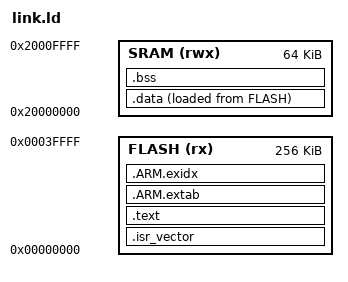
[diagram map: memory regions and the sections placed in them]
/*
 * link.ld -- LM3S6965 EVB memory map, as emulated by QEMU.
 *
 * 256 KiB flash at 0x00000000, 64 KiB SRAM at 0x20000000 accessed through
 * the core-coupled SRAM alias.  The stack grows down from the top of SRAM.
 */
ENTRY(Reset_Handler)

MEMORY
{
    FLASH (rx)  : ORIGIN = 0x00000000, LENGTH = 256K
    SRAM  (rwx) : ORIGIN = 0x20000000, LENGTH = 64K
}

_estack = ORIGIN(SRAM) + LENGTH(SRAM);

SECTIONS
{
    .isr_vector :
    {
        . = ALIGN(4);
        KEEP(*(.isr_vector))
        . = ALIGN(4);
    } > FLASH

    .text :
    {
        . = ALIGN(4);
        *(.text*)
        *(.rodata*)
        KEEP(*(.init))
        KEEP(*(.fini))
        . = ALIGN(4);
        _etext = .;
    } > FLASH

    .ARM.extab :
    {
        *(.ARM.extab* .gnu.linkonce.armextab.*)
    } > FLASH

    .ARM.exidx :
    {
        __exidx_start = .;
        *(.ARM.exidx* .gnu.linkonce.armexidx.*)
        __exidx_end = .;
    } > FLASH

    _sidata = LOADADDR(.data);

    .data :
    {
        . = ALIGN(4);
        _sdata = .;
        *(.data*)
        . = ALIGN(4);
        _edata = .;
    } > SRAM AT > FLASH

    .bss (NOLOAD) :
    {
        . = ALIGN(4);
        _sbss = .;
        *(.bss*)
        *(COMMON)
        . = ALIGN(4);
        _ebss = .;
    } > SRAM

    /DISCARD/ :
    {
        libc.a ( * )
        libm.a ( * )
        libgcc.a ( * )
    }

    .ARM.attributes 0 : { *(.ARM.attributes) }
}
